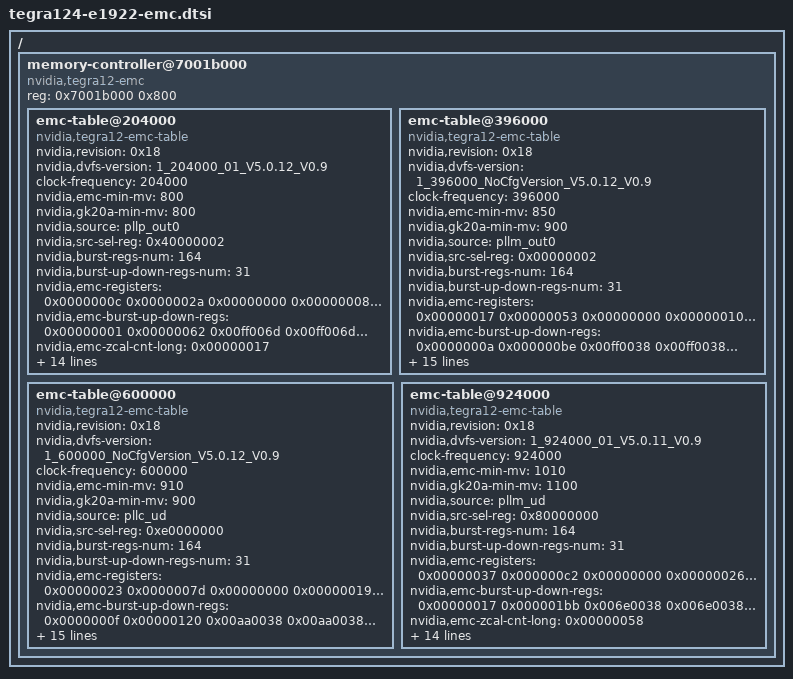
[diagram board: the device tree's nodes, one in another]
/ {
memory-controller@7001b000 {
		compatible = "nvidia,tegra12-emc";
		reg = <0x7001b000 0x800>;
		#address-cells = <1>;
		#size-cells = <0>;
		emc-table@204000 {
			compatible = "nvidia,tegra12-emc-table";
			nvidia,revision = <0x18>;
			nvidia,dvfs-version = "1_204000_01_V5.0.12_V0.9";
			clock-frequency = <204000>;
			nvidia,emc-min-mv = <800>;
			nvidia,gk20a-min-mv = <800>;
			nvidia,source = "pllp_out0";
			nvidia,src-sel-reg = <0x40000002>;
			nvidia,burst-regs-num = <164>;
			nvidia,burst-up-down-regs-num = <31>;
			nvidia,emc-registers = <
				0x0000000c
				0x0000002a
				0x00000000
				0x00000008
				0x00000003
				0x00000007
				0x00000008
				0x00000003
				0x0000000a
				0x00000003
				0x00000003
				0x00000002
				0x00000003
				0x00000000
				0x00000002
				0x00000002
				0x00000005
				0x00000003
				0x00000000
				0x00000003
				0x00000007
				0x00010000
				0x00000004
				0x00000000
				0x00000000
				0x00000000
				0x00000000
				0x00000002
				0x0000000e
				0x0000000f
				0x00000011
				0x00000304
				0x00000000
				0x000000c1
				0x00000002
				0x00000002
				0x00000003
				0x00000000
				0x00000001
				0x0000000c
				0x0000002d
				0x0000002d
				0x00000003
				0x00000004
				0x00000003
				0x00000009
				0x00000005
				0x00000003
				0x00000003
				0x0000055b
				0x00000000
				0x00000000
				0x00000000
				0x1363a296
				0x005800a0
				0x00008000
				0x00080000
				0x00080000
				0x00080000
				0x00080000
				0x00080000
				0x00080000
				0x00080000
				0x00080000
				0x00080000
				0x00080000
				0x00080000
				0x00080000
				0x00080000
				0x00080000
				0x00080000
				0x00080000
				0x00000000
				0x00000000
				0x00000000
				0x00000000
				0x00000000
				0x00000000
				0x00000000
				0x00000000
				0x000a8000
				0x000a8000
				0x00000000
				0x000a8000
				0x000a8000
				0x00000000
				0x00000000
				0x00000000
				0x00000000
				0x00000000
				0x00000000
				0x00000000
				0x00000000
				0x00000000
				0x00000000
				0x00000000
				0x00000000
				0x00000000
				0x00000000
				0x00000000
				0x00000000
				0x00000000
				0x00000000
				0x00000000
				0x00000000
				0x00000000
				0x00000000
				0x00000000
				0x00000000
				0x00000000
				0x00088000
				0x00088000
				0x00088000
				0x00088000
				0x00008c00
				0x00008800
				0x00008c00
				0x00008800
				0x00000200
				0x00000000
				0x00100100
				0x0130b018
				0x00000000
				0x00000000
				0x77ffc000
				0x00000303
				0x81f1f008
				0x07070000
				0x0000003f
				0x015ddddd
				0x51451400
				0x00514514
				0x00514514
				0x51451400
				0x0000003f
				0x00000000
				0x00000000
				0x00064000
				0x0000004a
				0x00cc0011
				0x00cc0011
				0x00000000
				0x00000004
				0x0000d3b3
				0x80000713
				0x0000000a
				0x01000003
				0x80000040
				0x00000001
				0x00000001
				0x00000006
				0x00000003
				0x00000005
				0x00000001
				0x00000002
				0x00000007
				0x00000003
				0x00000001
				0x00000005
				0x00000005
				0x05050103
				0x000a0506
				0x72e40a07
				0x001f0000
			>;
			nvidia,emc-burst-up-down-regs = <
			0x00000001
			0x00000062
			0x00ff006d
			0x00ff006d
			0x00ff003c
			0x00ff00af
			0x00ff004f
			0x00ff00af
			0x00ff004f
			0x004e0049
			0x00ff0080
			0x00ff0004
			0x00ff0004
			0x00080057
			0x000000ff
			0x00ff0004
			0x00ff0063
			0x00ff0036
			0x00ff0024
			0x00ff006b
			0x000000ff
			0x00000050
			0x00ff00ff
			0x00000050
			0x00ff00ff
			0x00d400ff
			0x00510050
			0x00ff00ff
			0x00ff00ff
			0x00ff00c6
			0x00ff006d
			>;
			nvidia,emc-zcal-cnt-long = <0x00000017>;
			nvidia,emc-acal-interval = <0x001fffff>;
			nvidia,emc-ctt-term_ctrl = <0x00000802>;
			nvidia,emc-cfg = <0xf3200000>;
			nvidia,emc-cfg-2 = <0x000008cf>;
			nvidia,emc-sel-dpd-ctrl = <0x0004013c>;
			nvidia,emc-cfg-dig-dll = <0x00580068>;
			nvidia,emc-bgbias-ctl0 = <0x00000008>;
			nvidia,emc-auto-cal-config2 = <0x00000000>;
			nvidia,emc-auto-cal-config3 = <0x00000000>;
			nvidia,emc-auto-cal-config = <0xa1430000>;
			nvidia,emc-mode-0 = <0x00000000>;
			nvidia,emc-mode-1 = <0x00010083>;
			nvidia,emc-mode-2 = <0x00020004>;
			nvidia,emc-mode-4 = <0x800b0000>;
		};
		emc-table@396000 {
			compatible = "nvidia,tegra12-emc-table";
			nvidia,revision = <0x18>;
			nvidia,dvfs-version = "1_396000_NoCfgVersion_V5.0.12_V0.9";
			clock-frequency = <396000>;
			nvidia,emc-min-mv = <850>;
			nvidia,gk20a-min-mv = <900>;
			nvidia,source = "pllm_out0";
			nvidia,src-sel-reg = <0x00000002>;
			nvidia,burst-regs-num = <164>;
			nvidia,burst-up-down-regs-num = <31>;
			nvidia,emc-registers = <
				0x00000017
				0x00000053
				0x00000000
				0x00000010
				0x00000007
				0x00000008
				0x00000008
				0x00000003
				0x0000000a
				0x00000007
				0x00000007
				0x00000003
				0x00000003
				0x00000000
				0x00000002
				0x00000002
				0x00000006
				0x00000003
				0x00000000
				0x00000002
				0x00000009
				0x00030000
				0x00000004
				0x00000000
				0x00000000
				0x00000000
				0x00000000
				0x00000001
				0x00000010
				0x00000012
				0x00000014
				0x000005d9
				0x00000000
				0x00000176
				0x00000002
				0x00000002
				0x00000007
				0x00000000
				0x00000001
				0x0000000e
				0x00000058
				0x00000058
				0x00000003
				0x00000006
				0x00000003
				0x00000012
				0x00000009
				0x00000003
				0x00000003
				0x00000a66
				0x00000000
				0x00000000
				0x00000000
				0x1363a096
				0x005800a0
				0x00008000
				0x00020000
				0x00020000
				0x00020000
				0x00020000
				0x00020000
				0x00020000
				0x00020000
				0x00020000
				0x00020000
				0x00020000
				0x00020000
				0x00020000
				0x00020000
				0x00020000
				0x00020000
				0x00020000
				0x00000000
				0x00000000
				0x00000000
				0x00000000
				0x00000000
				0x00000000
				0x00000000
				0x00000000
				0x00048000
				0x00048000
				0x00000000
				0x00048000
				0x00048000
				0x00000000
				0x00000000
				0x00000000
				0x00000000
				0x00000000
				0x00000000
				0x00000000
				0x00000000
				0x00000000
				0x00000000
				0x00000000
				0x00000000
				0x00000000
				0x00000000
				0x00000000
				0x00000000
				0x00000000
				0x00000000
				0x00000000
				0x00000000
				0x00000000
				0x00000000
				0x00000000
				0x00000000
				0x00000000
				0x00040000
				0x00040000
				0x00040000
				0x00040000
				0x00004000
				0x00004000
				0x00004000
				0x00004000
				0x00000200
				0x00000000
				0x00100100
				0x01231239
				0x00000000
				0x00000000
				0x77ffc000
				0x00000303
				0x81f1f008
				0x07070000
				0x0000003f
				0x015ddddd
				0x51451420
				0x00514514
				0x00514514
				0x51451400
				0x0000003f
				0x00000000
				0x00000000
				0x00064000
				0x0000008f
				0x018c0011
				0x018c0011
				0x00000000
				0x00000004
				0x000052a3
				0x80000cc7
				0x0000000b
				0x0f000005
				0x80000040
				0x00000002
				0x00000003
				0x0000000c
				0x00000007
				0x00000009
				0x00000001
				0x00000002
				0x00000007
				0x00000003
				0x00000001
				0x00000005
				0x00000005
				0x05050103
				0x000e090c
				0x72c6120d
				0x001f0000
			>;
			nvidia,emc-burst-up-down-regs = <
			0x0000000a
			0x000000be
			0x00ff0038
			0x00ff0038
			0x00ff003c
			0x00ff0090
			0x00ff0041
			0x00ff0090
			0x00ff0041
			0x00280049
			0x00ff0080
			0x00ff0004
			0x00ff0004
			0x0008002d
			0x000000ff
			0x00ff0004
			0x00ff0033
			0x00ff0022
			0x00ff0024
			0x00ff0037
			0x000000ff
			0x00000036
			0x00ff00ff
			0x00000036
			0x00ff00ff
			0x00d400ff
			0x00510029
			0x00ff00ff
			0x00ff00ff
			0x00ff0066
			0x00ff0038
			>;
			nvidia,emc-zcal-cnt-long = <0x00000028>;
			nvidia,emc-acal-interval = <0x001fffff>;
			nvidia,emc-ctt-term_ctrl = <0x00000802>;
			nvidia,emc-cfg = <0xf3300000>;
			nvidia,emc-cfg-2 = <0x00000897>;
			nvidia,emc-sel-dpd-ctrl = <0x0004001c>;
			nvidia,emc-cfg-dig-dll = <0x00580068>;
			nvidia,emc-bgbias-ctl0 = <0x00000000>;
			nvidia,emc-auto-cal-config2 = <0x00000000>;
			nvidia,emc-auto-cal-config3 = <0x00000000>;
			nvidia,emc-auto-cal-config = <0xa1430000>;
			nvidia,emc-mode-0 = <0x00000000>;
			nvidia,emc-mode-1 = <0x00010083>;
			nvidia,emc-mode-2 = <0x00020004>;
			nvidia,emc-mode-4 = <0x800b0000>;
		};
		emc-table@600000 {
			compatible = "nvidia,tegra12-emc-table";
			nvidia,revision = <0x18>;
			nvidia,dvfs-version = "1_600000_NoCfgVersion_V5.0.12_V0.9";
			clock-frequency = <600000>;
			nvidia,emc-min-mv = <910>;
			nvidia,gk20a-min-mv = <900>;
			nvidia,source = "pllc_ud";
			nvidia,src-sel-reg = <0xe0000000>;
			nvidia,burst-regs-num = <164>;
			nvidia,burst-up-down-regs-num = <31>;
			nvidia,emc-registers = <
				0x00000023
				0x0000007d
				0x00000000
				0x00000019
				0x0000000a
				0x0000000a
				0x0000000b
				0x00000004
				0x0000000f
				0x0000000a
				0x0000000a
				0x00000005
				0x00000004
				0x00000000
				0x00000004
				0x00000004
				0x0000000a
				0x00000004
				0x00000000
				0x00000003
				0x0000000d
				0x00070000
				0x00000005
				0x00000000
				0x00000000
				0x00000000
				0x00000000
				0x00000002
				0x00000014
				0x00000018
				0x0000001a
				0x000008e4
				0x00000000
				0x00000239
				0x00000004
				0x00000004
				0x0000000a
				0x00000000
				0x00000001
				0x00000013
				0x00000084
				0x00000084
				0x00000005
				0x00000009
				0x00000005
				0x0000001c
				0x0000000d
				0x00000003
				0x00000003
				0x00000fc0
				0x00000000
				0x00000000
				0x00000000
				0x1363a096
				0xe00e00b9
				0x00008000
				0x0000000a
				0x0000000a
				0x0000000a
				0x0000000a
				0x0000000a
				0x0000000a
				0x0000000a
				0x0000000a
				0x0000000a
				0x0000000a
				0x0000000a
				0x0000000a
				0x0000000a
				0x0000000a
				0x0000000a
				0x0000000a
				0x00000000
				0x00000000
				0x00000000
				0x00000000
				0x00000000
				0x00000000
				0x00000000
				0x00000000
				0x0000000e
				0x0000000e
				0x00000000
				0x00000010
				0x00000010
				0x00000000
				0x00000000
				0x00000000
				0x00000000
				0x00000000
				0x00000000
				0x00000000
				0x00000000
				0x00000000
				0x00000003
				0x00000003
				0x00000002
				0x00000002
				0x00000002
				0x00000001
				0x00000003
				0x00000001
				0x00000003
				0x00000003
				0x00000002
				0x00000002
				0x00000002
				0x00000001
				0x00000003
				0x00000001
				0x0000000b
				0x0000000b
				0x0000000b
				0x0000000b
				0x0000000c
				0x0000000b
				0x0000000c
				0x0000000b
				0x00000220
				0x00000000
				0x00100100
				0x0121103d
				0x00000000
				0x00000000
				0x77ffc004
				0x00000303
				0x81f1f008
				0x07070000
				0x0000003f
				0x015ddddd
				0x51451420
				0x00514514
				0x00514514
				0x51451400
				0x0000003f
				0x00000000
				0x00000000
				0x00064000
				0x000000d8
				0x02580014
				0x02580014
				0x00000000
				0x00000005
				0x000040a0
				0x800012d6
				0x00000010
				0x00000009
				0x80000040
				0x00000004
				0x00000005
				0x00000012
				0x0000000b
				0x0000000e
				0x00000002
				0x00000003
				0x0000000a
				0x00000003
				0x00000001
				0x00000006
				0x00000007
				0x07060103
				0x00140d12
				0x72c91b13
				0x001f0000
			>;
			nvidia,emc-burst-up-down-regs = <
			0x0000000f
			0x00000120
			0x00aa0038
			0x00aa0038
			0x00aa003c
			0x00aa0090
			0x00aa0041
			0x00aa0090
			0x00aa0041
			0x00270049
			0x00aa0080
			0x00aa0004
			0x00aa0004
			0x0008001d
			0x000000aa
			0x00aa0004
			0x00aa0022
			0x00aa0018
			0x00aa0024
			0x00aa0024
			0x000000aa
			0x00000036
			0x00aa00aa
			0x00000036
			0x00aa00aa
			0x00d400ff
			0x00510029
			0x00aa00aa
			0x00aa00aa
			0x00aa0065
			0x00aa0025
			>;
			nvidia,emc-zcal-cnt-long = <0x0000003a>;
			nvidia,emc-acal-interval = <0x001fffff>;
			nvidia,emc-ctt-term_ctrl = <0x00000802>;
			nvidia,emc-cfg = <0xf3300000>;
			nvidia,emc-cfg-2 = <0x0000089f>;
			nvidia,emc-sel-dpd-ctrl = <0x0004001c>;
			nvidia,emc-cfg-dig-dll = <0xe00e0069>;
			nvidia,emc-bgbias-ctl0 = <0x00000000>;
			nvidia,emc-auto-cal-config2 = <0x00000000>;
			nvidia,emc-auto-cal-config3 = <0x00000000>;
			nvidia,emc-auto-cal-config = <0xa1430000>;
			nvidia,emc-mode-0 = <0x00000000>;
			nvidia,emc-mode-1 = <0x000100e3>;
			nvidia,emc-mode-2 = <0x00020007>;
			nvidia,emc-mode-4 = <0x800b0000>;
		};
		emc-table@924000 {
			compatible = "nvidia,tegra12-emc-table";
			nvidia,revision = <0x18>;
			nvidia,dvfs-version = "1_924000_01_V5.0.11_V0.9";
			clock-frequency = <924000>;
			nvidia,emc-min-mv = <1010>;
			nvidia,gk20a-min-mv = <1100>;
			nvidia,source = "pllm_ud";
			nvidia,src-sel-reg = <0x80000000>;
			nvidia,burst-regs-num = <164>;
			nvidia,burst-up-down-regs-num = <31>;
			nvidia,emc-registers = <
				0x00000037
				0x000000c2
				0x00000000
				0x00000026
				0x00000010
				0x0000000f
				0x00000010
				0x00000006
				0x00000017
				0x00000010
				0x00000010
				0x00000009
				0x00000005
				0x00000000
				0x00000007
				0x00000007
				0x00000010
				0x00000005
				0x00000000
				0x00000005
				0x00000012
				0x000d0000
				0x00000007
				0x00000000
				0x00000000
				0x00000000
				0x00000000
				0x00000004
				0x00000019
				0x00000020
				0x00000022
				0x00000dd4
				0x00000000
				0x00000375
				0x00000006
				0x00000006
				0x00000010
				0x00000000
				0x00000001
				0x0000001b
				0x000000cc
				0x000000cc
				0x00000007
				0x0000000e
				0x00000007
				0x0000002d
				0x00000014
				0x00000003
				0x00000003
				0x00001842
				0x00000000
				0x00000000
				0x00000000
				0x1363a896
				0xe00400b9
				0x00008000
				0x00000004
				0x00000004
				0x00000004
				0x00000004
				0x00000004
				0x00000004
				0x00000004
				0x00000004
				0x00000004
				0x00000004
				0x00000004
				0x00000004
				0x00000004
				0x00000004
				0x00000004
				0x00000004
				0x00000000
				0x00000000
				0x00000000
				0x00000000
				0x00000000
				0x00000000
				0x00000000
				0x00000000
				0x0000400d
				0x0000400d
				0x00000000
				0x00000011
				0x00000011
				0x00000000
				0x00000000
				0x00000000
				0x00000000
				0x00000000
				0x00000000
				0x00000000
				0x00000000
				0x00000000
				0x00000004
				0x00000004
				0x00000004
				0x00000004
				0x00000004
				0x00000004
				0x00000004
				0x00000004
				0x00000004
				0x00000004
				0x00000004
				0x00000004
				0x00000004
				0x00000004
				0x00000004
				0x00000004
				0x00000009
				0x00000009
				0x00000009
				0x00000009
				0x0000000a
				0x00000009
				0x0000000a
				0x00000009
				0x00000220
				0x00000000
				0x00100100
				0x0120103d
				0x00000000
				0x00000000
				0x77ffc004
				0x00000303
				0x81f1f008
				0x07070000
				0x00000000
				0x015ddddd
				0x5d75d720
				0x00514514
				0x00514514
				0x5d75d700
				0x0000003f
				0x00000000
				0x00000000
				0x00064000
				0x0000014d
				0x039c0019
				0x039c0019
				0x00000000
				0x00000007
				0x00004080
				0x80001c77
				0x00000017
				0x0e00000d
				0x80000040
				0x00000007
				0x00000008
				0x0000001b
				0x00000012
				0x00000017
				0x00000004
				0x00000004
				0x0000000e
				0x00000004
				0x00000001
				0x00000009
				0x00000009
				0x09090104
				0x001e141b
				0x72ae2a1c
				0x001f0000
			>;
			nvidia,emc-burst-up-down-regs = <
			0x00000017
			0x000001bb
			0x006e0038
			0x006e0038
			0x006e003c
			0x006e0090
			0x006e0041
			0x006e0090
			0x006e0041
			0x00270049
			0x006e0080
			0x006e0004
			0x006e0004
			0x00080016
			0x0000006e
			0x006e0004
			0x006e0019
			0x006e0018
			0x006e0024
			0x006e001b
			0x0000006e
			0x00000036
			0x006e006e
			0x00000036
			0x006e006e
			0x00d400ff
			0x00510029
			0x006e006e
			0x006e006e
			0x006e0065
			0x006e001c
			>;
			nvidia,emc-zcal-cnt-long = <0x00000058>;
			nvidia,emc-acal-interval = <0x001fffff>;
			nvidia,emc-ctt-term_ctrl = <0x00000802>;
			nvidia,emc-cfg = <0xf3300000>;
			nvidia,emc-cfg-2 = <0x0000089f>;
			nvidia,emc-sel-dpd-ctrl = <0x0004001c>;
			nvidia,emc-cfg-dig-dll = <0xe0040069>;
			nvidia,emc-bgbias-ctl0 = <0x00000000>;
			nvidia,emc-auto-cal-config2 = <0x00000000>;
			nvidia,emc-auto-cal-config3 = <0x00000000>;
			nvidia,emc-auto-cal-config = <0xa1430000>;
			nvidia,emc-mode-0 = <0x00000000>;
			nvidia,emc-mode-1 = <0x00010083>;
			nvidia,emc-mode-2 = <0x0002001c>;
			nvidia,emc-mode-4 = <0x800b0000>;
		};
	};
};
